VERSION "1.0"

NS_ :

BS_:

BU_: BodyInputsECU DriverSwitchECU BCM

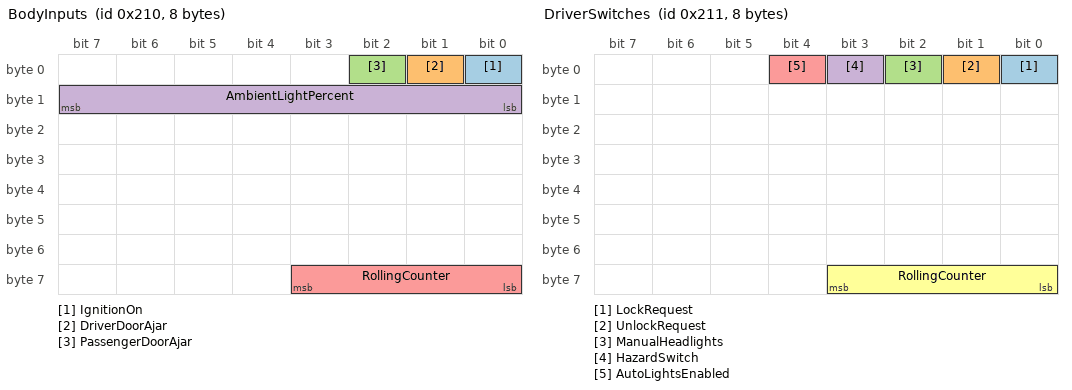
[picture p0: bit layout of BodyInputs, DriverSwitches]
BO_ 528 BodyInputs: 8 BodyInputsECU
 SG_ IgnitionOn : 0|1@1+ (1,0) [0|1] "" BCM
 SG_ DriverDoorAjar : 1|1@1+ (1,0) [0|1] "" BCM
 SG_ PassengerDoorAjar : 2|1@1+ (1,0) [0|1] "" BCM
 SG_ AmbientLightPercent : 8|8@1+ (1,0) [0|100] "%" BCM
 SG_ RollingCounter : 56|4@1+ (1,0) [0|15] "" BCM

BO_ 529 DriverSwitches: 8 DriverSwitchECU
 SG_ LockRequest : 0|1@1+ (1,0) [0|1] "" BCM
 SG_ UnlockRequest : 1|1@1+ (1,0) [0|1] "" BCM
 SG_ ManualHeadlights : 2|1@1+ (1,0) [0|1] "" BCM
 SG_ HazardSwitch : 3|1@1+ (1,0) [0|1] "" BCM
 SG_ AutoLightsEnabled : 4|1@1+ (1,0) [0|1] "" BCM
 SG_ RollingCounter : 56|4@1+ (1,0) [0|15] "" BCM

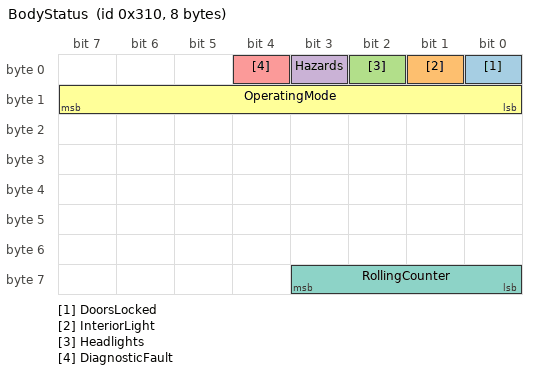
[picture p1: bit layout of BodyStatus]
BO_ 784 BodyStatus: 8 BCM
 SG_ DoorsLocked : 0|1@1+ (1,0) [0|1] "" BodyInputsECU,DriverSwitchECU
 SG_ InteriorLight : 1|1@1+ (1,0) [0|1] "" BodyInputsECU,DriverSwitchECU
 SG_ Headlights : 2|1@1+ (1,0) [0|1] "" BodyInputsECU,DriverSwitchECU
 SG_ Hazards : 3|1@1+ (1,0) [0|1] "" BodyInputsECU,DriverSwitchECU
 SG_ DiagnosticFault : 4|1@1+ (1,0) [0|1] "" BodyInputsECU,DriverSwitchECU
 SG_ OperatingMode : 8|8@1+ (1,0) [0|3] "" BodyInputsECU,DriverSwitchECU
 SG_ RollingCounter : 56|4@1+ (1,0) [0|15] "" BodyInputsECU,DriverSwitchECU

VAL_ 784 OperatingMode 0 "OFF" 1 "ACCESSORY" 2 "DRIVE" 3 "FAULT" ;
